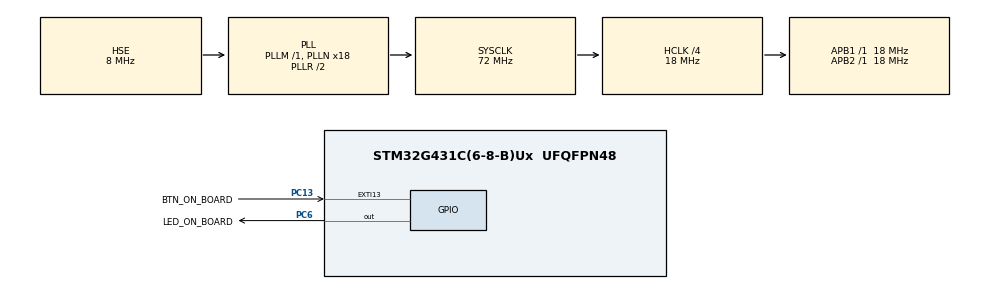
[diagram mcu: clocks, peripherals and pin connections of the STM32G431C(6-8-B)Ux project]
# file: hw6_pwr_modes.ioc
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IWDG.Prescaler=IWDG_PRESCALER_256
IWDG.Reload=625
Mcu.Family=STM32G4
Mcu.Name=STM32G431C(6-8-B)Ux
Mcu.Package=UFQFPN48
NVIC.EXTI15_10_IRQn=true\:8\:0\:true\:false\:true\:true\:true\:true
NVIC.PriorityGroup=NVIC_PRIORITYGROUP_4
PA13.Mode=Serial_Wire
PA13.Signal=SYS_JTMS-SWDIO
PA14.Mode=Serial_Wire
PA14.Signal=SYS_JTCK-SWCLK
PC13.GPIO_Label=BTN_ON_BOARD
PC13.GPIO_PuPd=GPIO_PULLDOWN
PC13.Signal=GPXTI13
PC14-OSC32_IN.Mode=LSE-External-Oscillator
PC14-OSC32_IN.Signal=RCC_OSC32_IN
PC15-OSC32_OUT.Mode=LSE-External-Oscillator
PC15-OSC32_OUT.Signal=RCC_OSC32_OUT
PC6.GPIO_Label=LED_ON_BOARD
PC6.Signal=GPIO_Output
PF0-OSC_IN.Mode=HSE-External-Oscillator
PF0-OSC_IN.Signal=RCC_OSC_IN
PF1-OSC_OUT.Mode=HSE-External-Oscillator
PF1-OSC_OUT.Signal=RCC_OSC_OUT
ProjectManager.HeapSize=0x200
ProjectManager.StackSize=0x400
ProjectManager.TargetToolchain=STM32CubeIDE
RCC.ADC12Freq_Value=72000000
RCC.AHBCLKDivider=RCC_SYSCLK_DIV4
RCC.AHBFreq_Value=18000000
RCC.APB1Freq_Value=18000000
RCC.APB1TimFreq_Value=18000000
RCC.APB2Freq_Value=18000000
RCC.APB2TimFreq_Value=18000000
RCC.CK48CLockSelection=RCC_USBCLKSOURCE_HSI48
RCC.CortexFreq_Value=18000000
RCC.EXTERNAL_CLOCK_VALUE=12288000
RCC.HCLKFreq_Value=18000000
RCC.HSE_VALUE=8000000
RCC.HSI48_VALUE=48000000
RCC.HSI_VALUE=16000000
RCC.PLLN=18
RCC.PLLSourceVirtual=RCC_PLLSOURCE_HSE
RCC.SYSCLKFreq_VALUE=72000000
RCC.SYSCLKSource=RCC_SYSCLKSOURCE_PLLCLK
RCC.USBFreq_Value=48000000
RCC.VCOOutputFreq_Value=144000000
VP_IWDG_VS_IWDG.Mode=IWDG_Activate
VP_SYS_VS_DBSignals.Mode=DisableDeadBatterySignals
board=custom

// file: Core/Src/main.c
/* USER CODE BEGIN Header */
/**
  ******************************************************************************
  * @file           : main.c
  * @brief          : Main program body
  ******************************************************************************
  * @attention
  *
  * Copyright (c) 2025 STMicroelectronics.
  * All rights reserved.
  *
  * This software is licensed under terms that can be found in the LICENSE file
  * in the root directory of this software component.
  * If no LICENSE file comes with this software, it is provided AS-IS.
  *
  ******************************************************************************
  */
/* USER CODE END Header */
#include "main.h"

/* USER CODE BEGIN Includes */
#include "stm32g4xx_ll_rcc.h"
#include "stm32g4xx_ll_pwr.h"
/* USER CODE END Includes */

IWDG_HandleTypeDef hiwdg;

void SystemClock_Config(void);
static void MX_GPIO_Init(void);
static void MX_IWDG_Init(void);
/* USER CODE BEGIN PFP */

void status_blink(uint32_t blink_count, uint32_t blink_time);
/* USER CODE END PFP */

int main(void)
{

  /* MCU Configuration--------------------------------------------------------*/

  /* Reset of all peripherals, Initializes the Flash interface and the Systick. */
  HAL_Init();

  /* Configure the system clock */
  SystemClock_Config();

  /* Initialize all configured peripherals */
  MX_GPIO_Init();
  //MX_IWDG_Init();

  /* Infinite loop */
  /* USER CODE BEGIN WHILE */

  //check cause
  //run mode
  if(LL_PWR_IsActiveFlag_SB())
  {
   status_blink(2, 500);
   LL_PWR_ClearFlag_SB();
  } else status_blink(2, 200);

  //sleep mode with wfi
  HAL_SuspendTick();
  HAL_PWR_EnterSLEEPMode(PWR_LOWPOWERREGULATOR_ON,PWR_SLEEPENTRY_WFI);
  HAL_ResumeTick();

  //stop mode
  status_blink(3, 500);
  HAL_SuspendTick();
  HAL_PWR_EnterSTOPMode(PWR_LOWPOWERREGULATOR_ON,PWR_SLEEPENTRY_WFI);
  SystemClock_Config();
  HAL_ResumeTick();

  //standbay mode
  status_blink(4, 500);
  MX_IWDG_Init();
  HAL_PWR_EnterSTANDBYMode();

  while (1)
  {
    /* USER CODE END WHILE */

  }
}

void SystemClock_Config(void)
{
  RCC_OscInitTypeDef RCC_OscInitStruct = {0};
  RCC_ClkInitTypeDef RCC_ClkInitStruct = {0};

  /** Configure the main internal regulator output voltage
  */
  HAL_PWREx_ControlVoltageScaling(PWR_REGULATOR_VOLTAGE_SCALE1);

  /** Initializes the RCC Oscillators according to the specified parameters
  * in the RCC_OscInitTypeDef structure.
  */
  RCC_OscInitStruct.OscillatorType = RCC_OSCILLATORTYPE_LSI|RCC_OSCILLATORTYPE_HSE;
  RCC_OscInitStruct.HSEState = RCC_HSE_ON;
  RCC_OscInitStruct.LSIState = RCC_LSI_ON;
  RCC_OscInitStruct.PLL.PLLState = RCC_PLL_ON;
  RCC_OscInitStruct.PLL.PLLSource = RCC_PLLSOURCE_HSE;
  RCC_OscInitStruct.PLL.PLLM = RCC_PLLM_DIV1;
  RCC_OscInitStruct.PLL.PLLN = 18;
  RCC_OscInitStruct.PLL.PLLP = RCC_PLLP_DIV2;
  RCC_OscInitStruct.PLL.PLLQ = RCC_PLLQ_DIV2;
  RCC_OscInitStruct.PLL.PLLR = RCC_PLLR_DIV2;
  if (HAL_RCC_OscConfig(&RCC_OscInitStruct) != HAL_OK)
  {
    Error_Handler();
  }

  /** Initializes the CPU, AHB and APB buses clocks
  */
  RCC_ClkInitStruct.ClockType = RCC_CLOCKTYPE_HCLK|RCC_CLOCKTYPE_SYSCLK
                              |RCC_CLOCKTYPE_PCLK1|RCC_CLOCKTYPE_PCLK2;
  RCC_ClkInitStruct.SYSCLKSource = RCC_SYSCLKSOURCE_PLLCLK;
  RCC_ClkInitStruct.AHBCLKDivider = RCC_SYSCLK_DIV4;
  RCC_ClkInitStruct.APB1CLKDivider = RCC_HCLK_DIV1;
  RCC_ClkInitStruct.APB2CLKDivider = RCC_HCLK_DIV1;

  if (HAL_RCC_ClockConfig(&RCC_ClkInitStruct, FLASH_LATENCY_0) != HAL_OK)
  {
    Error_Handler();
  }
}

static void MX_IWDG_Init(void)
{

  hiwdg.Instance = IWDG;
  hiwdg.Init.Prescaler = IWDG_PRESCALER_256;
  hiwdg.Init.Window = 4095;
  hiwdg.Init.Reload = 625;
  if (HAL_IWDG_Init(&hiwdg) != HAL_OK)
  {
    Error_Handler();
  }

}

static void MX_GPIO_Init(void)
{
  GPIO_InitTypeDef GPIO_InitStruct = {0};

  /* GPIO Ports Clock Enable */
  __HAL_RCC_GPIOC_CLK_ENABLE();
  __HAL_RCC_GPIOF_CLK_ENABLE();
  __HAL_RCC_GPIOG_CLK_ENABLE();
  __HAL_RCC_GPIOA_CLK_ENABLE();
  __HAL_RCC_GPIOB_CLK_ENABLE();

  /*Configure GPIO pin Output Level */
  HAL_GPIO_WritePin(LED_ON_BOARD_GPIO_Port, LED_ON_BOARD_Pin, GPIO_PIN_RESET);

  /*Configure GPIO pin : BTN_ON_BOARD_Pin */
  GPIO_InitStruct.Pin = BTN_ON_BOARD_Pin;
  GPIO_InitStruct.Mode = GPIO_MODE_IT_RISING;
  GPIO_InitStruct.Pull = GPIO_PULLDOWN;
  HAL_GPIO_Init(BTN_ON_BOARD_GPIO_Port, &GPIO_InitStruct);

  /*Configure GPIO pin : PG10 */
  GPIO_InitStruct.Pin = GPIO_PIN_10;
  GPIO_InitStruct.Mode = GPIO_MODE_ANALOG;
  GPIO_InitStruct.Pull = GPIO_NOPULL;
  HAL_GPIO_Init(GPIOG, &GPIO_InitStruct);

  /*Configure GPIO pins : PA0 PA1 PA2 PA3
                           PA4 PA5 PA6 PA7
                           PA8 PA9 PA10 PA11
                           PA12 PA15 */
  GPIO_InitStruct.Pin = GPIO_PIN_0|GPIO_PIN_1|GPIO_PIN_2|GPIO_PIN_3
                          |GPIO_PIN_4|GPIO_PIN_5|GPIO_PIN_6|GPIO_PIN_7
                          |GPIO_PIN_8|GPIO_PIN_9|GPIO_PIN_10|GPIO_PIN_11
                          |GPIO_PIN_12|GPIO_PIN_15;
  GPIO_InitStruct.Mode = GPIO_MODE_ANALOG;
  GPIO_InitStruct.Pull = GPIO_NOPULL;
  HAL_GPIO_Init(GPIOA, &GPIO_InitStruct);

  /*Configure GPIO pins : PC4 PC10 PC11 */
  GPIO_InitStruct.Pin = GPIO_PIN_4|GPIO_PIN_10|GPIO_PIN_11;
  GPIO_InitStruct.Mode = GPIO_MODE_ANALOG;
  GPIO_InitStruct.Pull = GPIO_NOPULL;
  HAL_GPIO_Init(GPIOC, &GPIO_InitStruct);

  /*Configure GPIO pins : PB0 PB1 PB2 PB10
                           PB11 PB12 PB13 PB14
                           PB15 PB3 PB4 PB5
                           PB6 PB7 PB8 PB9 */
  GPIO_InitStruct.Pin = GPIO_PIN_0|GPIO_PIN_1|GPIO_PIN_2|GPIO_PIN_10
                          |GPIO_PIN_11|GPIO_PIN_12|GPIO_PIN_13|GPIO_PIN_14
                          |GPIO_PIN_15|GPIO_PIN_3|GPIO_PIN_4|GPIO_PIN_5
                          |GPIO_PIN_6|GPIO_PIN_7|GPIO_PIN_8|GPIO_PIN_9;
  GPIO_InitStruct.Mode = GPIO_MODE_ANALOG;
  GPIO_InitStruct.Pull = GPIO_NOPULL;
  HAL_GPIO_Init(GPIOB, &GPIO_InitStruct);

  /*Configure GPIO pin : LED_ON_BOARD_Pin */
  GPIO_InitStruct.Pin = LED_ON_BOARD_Pin;
  GPIO_InitStruct.Mode = GPIO_MODE_OUTPUT_PP;
  GPIO_InitStruct.Pull = GPIO_NOPULL;
  GPIO_InitStruct.Speed = GPIO_SPEED_FREQ_LOW;
  HAL_GPIO_Init(LED_ON_BOARD_GPIO_Port, &GPIO_InitStruct);

  /* EXTI interrupt init*/
  HAL_NVIC_SetPriority(EXTI15_10_IRQn, 8, 0);
  HAL_NVIC_EnableIRQ(EXTI15_10_IRQn);

}

/* USER CODE BEGIN 4 */

void status_blink(uint32_t blink_count, uint32_t blink_time)
{
  for(uint8_t i = 0; i < blink_count * 2; i++)
  {
    HAL_GPIO_TogglePin(LED_ON_BOARD_GPIO_Port, LED_ON_BOARD_Pin);
    HAL_Delay(blink_time);
  }
  HAL_GPIO_WritePin(LED_ON_BOARD_GPIO_Port, LED_ON_BOARD_Pin, GPIO_PIN_SET);
  HAL_Delay(2000);
  HAL_GPIO_WritePin(LED_ON_BOARD_GPIO_Port, LED_ON_BOARD_Pin, GPIO_PIN_RESET);
}

/* USER CODE END 4 */

void Error_Handler(void)
{
  __disable_irq();
  while (1)
  {
  }
}
